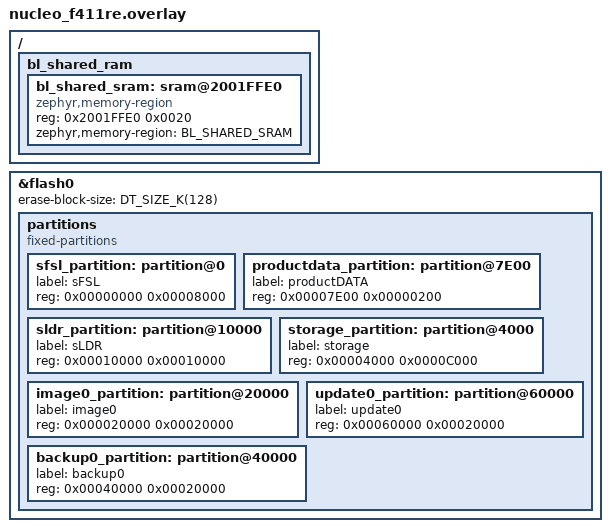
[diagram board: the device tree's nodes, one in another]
/*
 * Copyright (c) 2022 Laczen
 *
 * SPDX-License-Identifier: Apache-2.0
 */

#include "../app.overlay"

&flash0 {
	/delete-property/ erase-block-size;
	erase-block-size = <DT_SIZE_K(128)>;

	partitions {
		compatible = "fixed-partitions";
		#address-cells = <1>;
		#size-cells = <1>;

		sfsl_partition: partition@0 {
			label = "sFSL";
			reg = <0x00000000 0x00008000>;
		};

		productdata_partition: partition@7E00 {
			label = "productDATA";
			reg = <0x00007E00 0x00000200>;
		};

		sldr_partition: partition@10000 {
			label = "sLDR";
			reg = <0x00010000 0x00010000>;
		};

		storage_partition: partition@4000 {
			label = "storage";
			reg = <0x00004000 0x0000C000>;
		};

		image0_partition: partition@20000 {
			label = "image0";
			reg = <0x000020000 0x00020000>;
		};

		update0_partition: partition@60000 {
			label = "update0";
			reg = <0x00060000 0x00020000>;
		};

		backup0_partition: partition@40000 {
			label = "backup0";
			reg = <0x00040000 0x00020000>;
		};
	};
};

/ {
	bl_shared_ram {
		#address-cells = < 0x1 >;
		#size-cells = < 0x1 >;

		bl_shared_sram: sram@2001FFE0 {
			compatible = "zephyr,memory-region", "mmio-sram";
			reg = < 0x2001FFE0 0x0020 >;
			zephyr,memory-region = "BL_SHARED_SRAM";
		};
	};
};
